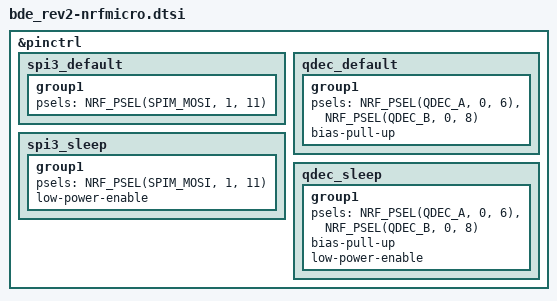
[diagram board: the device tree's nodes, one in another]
/*
 * Copyright (c) 2022 The ZMK Contributors
 *
 * SPDX-License-Identifier: MIT
 */

#include "bde_rev2-nrf52.dtsi"

&pinctrl {
    spi3_default: spi3_default {
        group1 {
            psels = <NRF_PSEL(SPIM_MOSI, 1, 11)>;
        };
    };

    spi3_sleep: spi3_sleep {
        group1 {
            psels = <NRF_PSEL(SPIM_MOSI, 1, 11)>;
            low-power-enable;
        };
    };

    qdec_default: qdec_default {
        group1 {
            psels = <NRF_PSEL(QDEC_A, 0, 6)>,
                    <NRF_PSEL(QDEC_B, 0, 8)>;
            bias-pull-up;
        };
    };

    qdec_sleep: qdec_sleep {
        group1 {
            psels = <NRF_PSEL(QDEC_A, 0, 6)>,
                    <NRF_PSEL(QDEC_B, 0, 8)>;
            bias-pull-up;
            low-power-enable;
        };
    };
};
